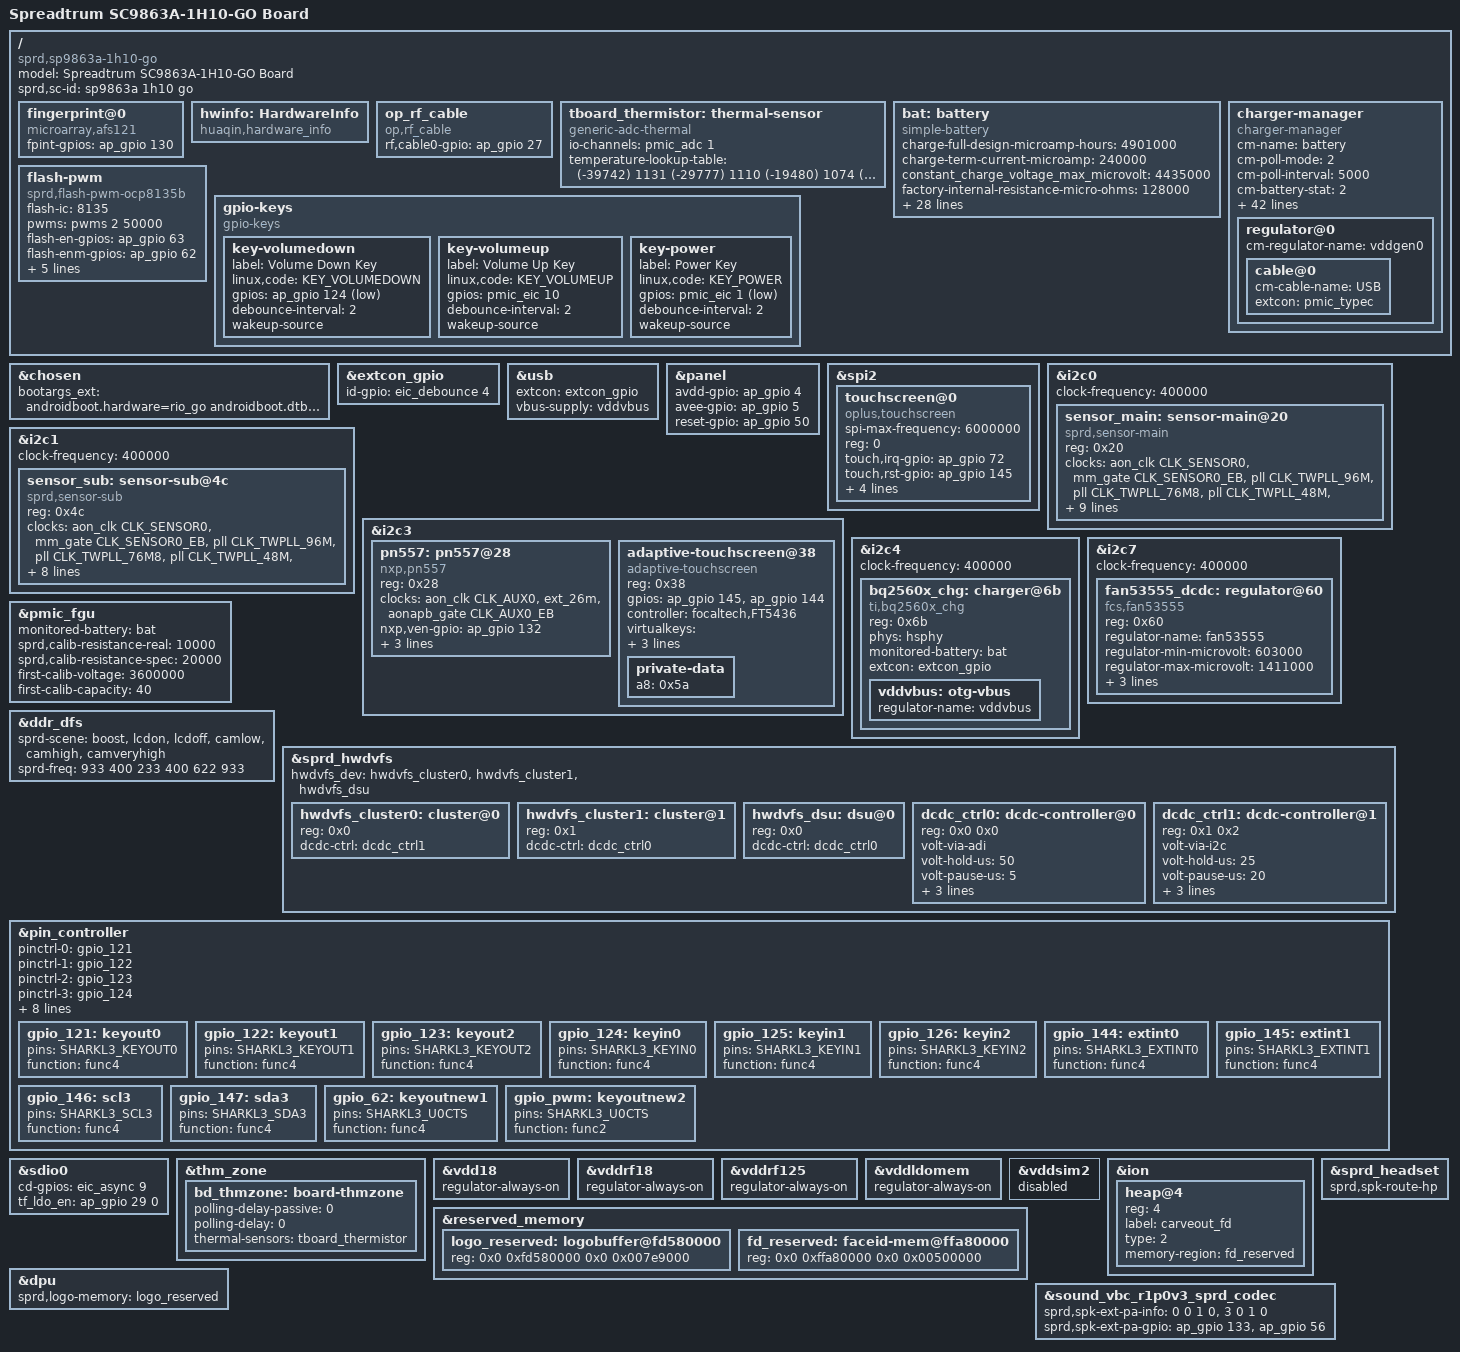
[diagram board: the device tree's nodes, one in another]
/dts-v1/;
/plugin/;

#include <dt-bindings/input/input.h>
#include <dt-bindings/gpio/gpio.h>
#include <dt-bindings/clock/sprd,sc9863a-clk.h>
#include <dt-bindings/pinctrl/pinctrl-sprd.h>
#include "lcd/lcd_jd9365t_ctc_mipi_hd.dtsi"
#include "lcd/lcd_hx83112a_boe_mipi_hd.dtsi"
#include "lcd/lcd_hx83112a_inx_mipi_hd.dtsi"
#include "lcd/lcd_ft8615_inx_mipi_hd.dtsi"
#include "lcd/lcd_ILI9882N_boe_mipi_hd.dtsi"
#include "lcd/lcd_icnl9911C_truly_mipi_hd.dtsi"
#include "lcd/lcd_ft8006s_boe_mipi_hd.dtsi"
#include "lcd/lcd_ft8722_boe_mipi_hd.dtsi"
#include "lcd/lcd_ft8006saa_truly_mipi_hd.dtsi"
#include "lcd/lcd_nt35695_truly_mipi_fhd.dtsi"
#include "lcd/lcd_nt35532_truly_mipi_fhd.dtsi"
#include "lcd/lcd_nt35596_boe_mipi_fhd.dtsi"
#include "lcd/lcd_dummy_mipi.dtsi"


/ {
	model = "Spreadtrum SC9863A-1H10-GO Board";
	compatible = "sprd,sp9863a-1h10-go", "sprd,sc9863a";
	sprd,sc-id = "sp9863a 1h10 go";

	fragment {
		target-path = "/";
		__overlay__ {
			fingerprint@0 {
				compatible = "microarray,afs121";
				fpint-gpios = <&ap_gpio 130 0>;
			};

			hwinfo:HardwareInfo {
				compatible = "huaqin,hardware_info";
				status = "okay";
			};

			op_rf_cable {
				compatible = "op,rf_cable";
				status = "okay";
				rf,cable0-gpio = <&ap_gpio 27 0>;
			};

			tboard_thermistor:thermal-sensor {
				compatible = "generic-adc-thermal";
				#thermal-sensor-cells = <0>;
				io-channels = <&pmic_adc 1>;
				io-channel-names = "sensor-channel";
				temperature-lookup-table = <	(-39742) 1131
								(-29777) 1110
								(-19480) 1074
								(-4679) 983
								10110 838
								24805 654
								44922 413
								54903 316
								64895 238
								74884 178
								84883 133
								94883 100
								104880 75
								114889 57
								124872 43 >;
			};

			bat: battery {
				compatible = "simple-battery";
				charge-full-design-microamp-hours = <4901000>;
				charge-term-current-microamp = <240000>;
				constant_charge_voltage_max_microvolt = <4435000>;
				factory-internal-resistance-micro-ohms = <128000>;
				voltage-min-design-microvolt = <3450000>;
				ocv-capacity-celsius = <20>;
				ocv-capacity-table-0 = <4381000 100>, <4325000 95>, <4268000 90>,
							<4211000 85>, <4154000 80>, <4100000 75>,
							<4049000 70>, <4001000 65>, <3951000 60>,
							<3898000 55>, <3866000 50>, <3840000 45>,
							<3819000 40>, <3802000 35>, <3786000 30>,
							<3765000 25>, <3744000 20>, <3720000 15>,
							<3691000 10>, <3679000 5>, <3400000 0>;
				voltage-temp-table = <1307738 700>, <1203814 750>, <1095466 800>,
							<986111 850>, <878558 900>, <775112 950>,
							<678460 1000>, <590240 1050>, <510772 1100>,
							<440156 1150>, <378279 1200>, <324561 1250>,
							<278079 1300>, <238259 1350>, <204266 1400>,
							<175208 1450>, <150459 1500>, <129410 1550>,
							<111497 1600>, <96484 1650>, <81275 1700>,
							<72771 1750>, <63423 1800>, <55444 1850>,
							<48599 1900>, <42668 1950>, <37552 2000>;
				capacity-temp-table =<45 100>, <25 100>, <10 99>, <0 91>, <(-10) 86>, <(-20) 64>;
				resistance-temp-table =<45 100>, <25 100>, <10 225>, <0 919>, <(-10) 981>, <(-20) 1097>;
				charge-sdp-current-microamp = <500000 2000000>;
				charge-dcp-current-microamp = <2100000 2200000>;
				charge-cdp-current-microamp = <1500000 2100000>;
				charge-unknown-current-microamp = <2100000 2100000>;
			};

			charger-manager {
				status = "okay";
				compatible = "charger-manager";
				cm-name = "battery";
				cm-poll-mode = <2>;
				cm-poll-interval = <5000>;
				cm-battery-stat = <2>;

				cm-fullbatt-vchkdrop-ms = <30000>;
				cm-fullbatt-vchkdrop-volt = <75000>;
				cm-fullbatt-voltage = <4410000>;
				cm-fullbatt-current = <260000>;
				cm-fullbatt-capacity = <100>;

				cm-num-chargers = <1>;
				cm-chargers = "bq2560x_charger";
				cm-fuel-gauge = "sc27xx-fgu";

				/* in deci centigrade */
				cm-battery-cold = <200>;
				cm-battery-cold-in-minus;
				cm-battery-hot = <800>;
				cm-battery-temp-diff = <100>;

				/* Allow charging for 6hr */
				cm-charging-max = <72000000>;
				/* recovery charging after stop charging 45min */
				cm-discharging-max = <2700000>;

				/* the interval to feed charger watchdog */
				cm-wdt-interval = <60>;

				/* drop voltage in microVolts to allow shutdown */
				cm-shutdown-voltage = <3350000>;

				/* when 99% of the time is exceeded, it will be forced to 100% */
				cm-tickle-time-out = <1500>;

				/* how much time to allow capacity change */
				cm-one-cap-time = <30>;

				/* when the safe charging voltage is exceeded, stop charging */
				cm-charge-voltage-max = <6500000>;
				/* drop voltage in microVolts to restart charging */
				cm-charge-voltage-drop = <700000>;
				cm-dcp-jeita-temp-table = <1000 1000 0 4435000>,
					<1150 1150 1400000 4435000>,
					<1450 1450 2100000 4435000>,
					<1530 1530 1400000 4130000>;
				cm-sdp-jeita-temp-table = <1000 1000 0 4435000>,
					<1150 1150 540000 4435000>,
					<1450 1450 540000 4435000>,
					<1530 1530 540000 4130000>;
				cm-cdp-jeita-temp-table = <1000 1000 0 4435000>,
					<1150 1150 1400000 4435000>,
					<1450 1450 1500000 4435000>,
					<1530 1530 1400000 4130000>;
				cm-unknown-jeita-temp-table = <1000 1000 0 4435000>,
					<1150 1150 1400000 4435000>,
					<1450 1450 2100000 4435000>,
					<1530 1530 1400000 4130000>;

				monitored-battery = <&bat>;
				cm-capacity-track;

				cm-cap-remap-table = <1 2 3>, <2 3 2>, <98 99 2>, <99 100 3>;

				io-channels = <&pmic_adc 3>;
				io-channel-names = "batt_id-channel";

				regulator@0 {
					cm-regulator-name = "vddgen0";
					cable@0 {
						cm-cable-name = "USB";
						extcon = <&pmic_typec>;
					};
				};
			};

			flash-pwm {
				compatible = "sprd,flash-pwm-ocp8135b";
				flash-ic = <8135>;
				pwms = <&pwms 2 50000>;
				flash-en-gpios = <&ap_gpio 63 0>;
				flash-enm-gpios = <&ap_gpio 62 0>;

				pinctrl-names = "gpio_pwm","gpio_62";
				pinctrl-0 = <&gpio_pwm>;
				pinctrl-1 = <&gpio_62>;
				board_id1 = <&ap_gpio 34 0>;
				board_id2 = <&ap_gpio 35 0>;
				board_id3 = <&ap_gpio 39 0>;
				status = "okay";
			};

			gpio-keys {
				compatible = "gpio-keys";

				key-volumedown {
					label = "Volume Down Key";
					linux,code = <KEY_VOLUMEDOWN>;
					gpios = <&ap_gpio 124 GPIO_ACTIVE_LOW>;
					debounce-interval = <2>;
					wakeup-source;
				};

				key-volumeup {
					label = "Volume Up Key";
					linux,code = <KEY_VOLUMEUP>;
					gpios = <&pmic_eic 10 GPIO_ACTIVE_HIGH>;
					debounce-interval = <2>;
					wakeup-source;
				};

				key-power {
					label = "Power Key";
					linux,code = <KEY_POWER>;
					gpios = <&pmic_eic 1 GPIO_ACTIVE_LOW>;
					debounce-interval = <2>;
					wakeup-source;
				};
			};
		};
	};
};

&chosen {
	bootargs_ext = "androidboot.hardware=rio_go androidboot.dtbo_idx=0";
};

&extcon_gpio {
 	id-gpio = <&eic_debounce 4 GPIO_ACTIVE_HIGH>;
 };
 
&usb {
	extcon = <&extcon_gpio>;
	vbus-supply = <&vddvbus>;
};

&panel {
	avdd-gpio = <&ap_gpio 4 GPIO_ACTIVE_HIGH>;
	avee-gpio = <&ap_gpio 5 GPIO_ACTIVE_HIGH>;
	reset-gpio = <&ap_gpio 50 GPIO_ACTIVE_HIGH>;
};

&spi2 {
	status = "okay";
	
        touchscreen@0 {
			compatible = "oplus,touchscreen";
			spi-max-frequency = <6000000>;
			reg = <0>;
			touch,irq-gpio = <&ap_gpio 72 0>;
			touch,rst-gpio = <&ap_gpio 145 0>;
			touch,panel-coords = <0 720 0 1600>;
			himax,display-coords = <0 720 0 1600>;
			focaltech,max-touch-number = <10>;
			focaltech,display-coords =  <0 0 720 1600>;
			status ="okay";
		};
};

&i2c0 {
	status = "okay";
	clock-frequency = <400000>;

	sensor_main: sensor-main@20 {
		compatible = "sprd,sensor-main";
		reg = <0x20>;
		clock-names = "clk_src","sensor_eb",
			"clk_96m","clk_76m8",
			"clk_48m","clk_26m";
		clocks = <&aon_clk CLK_SENSOR0>, <&mm_gate CLK_SENSOR0_EB>,
			<&pll CLK_TWPLL_96M>,<&pll CLK_TWPLL_76M8>,
			<&pll CLK_TWPLL_48M>,<&ext_26m>;
		vddio-supply = <&vddcamio>;
		vddcama-supply = <&vddcama>;
		vddcamd-supply = <&vddcamd>;
		vddcammot-supply = <&vddcammot>;
		sprd,phyid = <1>;
		csi = <&csi0>;
		reset-gpios = <&ap_gpio 44 0>;
		power-down-gpios = <&ap_gpio 46 0>;
	};
};

&i2c1 {
	status = "okay";
	clock-frequency = <400000>;

	sensor_sub: sensor-sub@4c {
		compatible = "sprd,sensor-sub";
		reg = <0x4c>;
		clock-names = "clk_src","sensor_eb",
			"clk_96m","clk_76m8",
			"clk_48m","clk_26m";
		clocks = <&aon_clk CLK_SENSOR0>, <&mm_gate CLK_SENSOR0_EB>,
			<&pll CLK_TWPLL_96M>,<&pll CLK_TWPLL_76M8>,
			<&pll CLK_TWPLL_48M>,<&ext_26m>;
		vddio-supply = <&vddcamio>;
		vddcama-supply = <&vddcama>;
		vddcamd-supply = <&vddcamd>;
		/*vddcammot-supply = <&vddcammot>;*/
		sprd,phyid = <2>;
		csi = <&csi0>;
		reset-gpios = <&ap_gpio 45 0>;
		power-down-gpios = <&ap_gpio 40 0>;
	};
};

&i2c3 {
	status = "okay";

        pn557: pn557@28{
                compatible = "nxp,pn557";
                reg = <0x28>;
                clock-names = "pn557_clk","source","enable";
                clocks = <&aon_clk CLK_AUX0>, <&ext_26m>, <&aonapb_gate CLK_AUX0_EB>;
                nxp,ven-gpio = <&ap_gpio 132 0>;
                nxp,irq-gpio = <&ap_gpio 121 0>;
                nxp,firm-gpio = <&ap_gpio 65 0>;
                nxp,clkreq-gpio = <&ap_gpio 66 0>;
        };

	adaptive-touchscreen@38 {
		compatible = "adaptive-touchscreen";
		reg = <0x38>;
		gpios = <&ap_gpio 145 GPIO_ACTIVE_HIGH
			&ap_gpio 144 GPIO_ACTIVE_HIGH>;
		controller = "focaltech,FT5436";
		virtualkeys = <580 60 1320 60 45
			172 360 1320 60 45
			158 600 1320 60 45>;
		surface-width = <720>;
		surface-height = <1280>;

		private-data {
			a8 = /bits/ 8 <0x5a>;
		};
	};

};

&i2c4 {
	status = "okay";
	clock-frequency = <400000>;

	      bq2560x_chg: charger@6b {
              compatible = "ti,bq2560x_chg";
              reg = <0x6b>;
              phys = <&hsphy>;
              monitored-battery = <&bat>;
              extcon = <&extcon_gpio>;
              vddvbus:otg-vbus{
                     regulator-name = "vddvbus";
               };
       };
};

&i2c7 {
	status = "okay";
	clock-frequency = <400000>;

	fan53555_dcdc: regulator@60 {
		compatible = "fcs,fan53555";
		reg = <0x60>;
		regulator-name = "fan53555";
		regulator-min-microvolt = <603000>;
		regulator-max-microvolt = <1411000>;
		regulator-ramp-delay = <64000>;
		regulator-always-on;
		fcs,suspend-voltage-selector = <1>;
	};
};

&pmic_fgu {
	monitored-battery = <&bat>;
	sprd,calib-resistance-real = <10000>;
	sprd,calib-resistance-spec = <20000>;
	first-calib-voltage = <3600000>;
	first-calib-capacity = <40>;
};
/*
&panel {
	sprd,backlight = <&pwm_backlight>;
	sprd,surface-width = <720>;
	sprd,surface-height = <1280>;
};*/

&ddr_dfs {
	sprd-scene = "boost", "lcdon", "lcdoff", "camlow",
			"camhigh", "camveryhigh";
	sprd-freq = <933 400 233 400 622 933>;
};

&sprd_hwdvfs {
	hwdvfs_dev = <&hwdvfs_cluster0>,
		<&hwdvfs_cluster1>,
		<&hwdvfs_dsu>;

	hwdvfs_cluster0: cluster@0 {
		reg = <0x0>;
		dcdc-ctrl = <&dcdc_ctrl1>;
	};

	hwdvfs_cluster1: cluster@1 {
		reg = <0x1>;
		dcdc-ctrl = <&dcdc_ctrl0>;
	};

	hwdvfs_dsu: dsu@0 {
		reg = <0x0>;
		dcdc-ctrl = <&dcdc_ctrl0>;
	};

	dcdc_ctrl0: dcdc-controller@0 {
		reg = <0x0 0x0>;
		volt-via-adi;
		volt-hold-us = <50>;
		volt-pause-us = <5>;
		volt-timeout-us = <800>;
		volt-stable-us  = <5>;
		volt-max-step-microvolt = <25000>;
	};

	dcdc_ctrl1: dcdc-controller@1 {
		reg = <0x1 0x2>;
		volt-via-i2c;
		volt-hold-us = <25>;
		volt-pause-us = <20>;
		volt-timeout-us = <800>;
		volt-stable-us  = <25>;
		volt-max-step-microvolt = <1200004>;
	};
};

&pin_controller {
	pinctrl-names =
	/* keyout0 ~ keyout2 */
	"gpio_121", "gpio_122", "gpio_123",
	/* keyin0 ~ keyin2 */
	"gpio_124", "gpio_125", "gpio_126",
	/* extint0, extint1, scl3, sda3 */
	"gpio_144", "gpio_145", "gpio_146", "gpio_147", "gpio_62", "gpio_pwm";
	pinctrl-0 = <&gpio_121>;
	pinctrl-1 = <&gpio_122>;
	pinctrl-2 = <&gpio_123>;
	pinctrl-3 = <&gpio_124>;
	pinctrl-4 = <&gpio_125>;
	pinctrl-5 = <&gpio_126>;
	pinctrl-6 = <&gpio_144>;
	pinctrl-7 = <&gpio_145>;
	pinctrl-8 = <&gpio_146>;
	pinctrl-9 = <&gpio_147>;
	pinctrl-10 = <&gpio_62>;
	pinctrl-11 = <&gpio_pwm>;

	gpio_121: keyout0 {
		pins = "SHARKL3_KEYOUT0";
		function = "func4";
	};

	gpio_122: keyout1 {
		pins = "SHARKL3_KEYOUT1";
		function = "func4";
	};

	gpio_123: keyout2 {
		pins = "SHARKL3_KEYOUT2";
		function = "func4";
	};

	gpio_124: keyin0 {
		pins = "SHARKL3_KEYIN0";
		function = "func4";
	};

	gpio_125: keyin1 {
		pins = "SHARKL3_KEYIN1";
		function = "func4";
	};

	gpio_126: keyin2 {
		pins = "SHARKL3_KEYIN2";
		function = "func4";
	};

	gpio_144: extint0 {
		pins = "SHARKL3_EXTINT0";
		function = "func4";
	};

	gpio_145: extint1 {
		pins = "SHARKL3_EXTINT1";
		function = "func4";
	};

	gpio_146: scl3 {
		pins = "SHARKL3_SCL3";
		function = "func4";
	};

	gpio_147: sda3 {
		pins = "SHARKL3_SDA3";
		function = "func4";
	};

	gpio_62: keyoutnew1 {
		pins = "SHARKL3_U0CTS";
		function = "func4";
	};

	gpio_pwm: keyoutnew2 {
		pins = "SHARKL3_U0CTS";
		function = "func2";
	};

};

&sdio0 {
	cd-gpios = <&eic_async 9 0>;
	tf_ldo_en = <&ap_gpio 29 0>;
};

&thm_zone {
	bd_thmzone: board-thmzone {
		polling-delay-passive = <0>;
		polling-delay = <0>;
		thermal-sensors = <&tboard_thermistor>;
	};
};

&vdd18 {
	regulator-always-on;
};

&vddrf18 {
	regulator-always-on;
};

&vddrf125 {
	regulator-always-on;
};

&vddldomem {
	regulator-always-on;
};

&vddsim2 {
	status = "disabled";
};

&reserved_memory {
	logo_reserved: logobuffer@fd580000{
		reg = <0x0 0xfd580000 0x0 0x007e9000>;
	};

	fd_reserved: faceid-mem@ffa80000 {
		reg = <0x0 0xffa80000 0x0 0x00500000>;
	};
};

&ion {
	heap@4 {
		reg = <4>;
		label = "carveout_fd";
		type = <2>;
		memory-region = <&fd_reserved>;
	};
};

&dpu {
	sprd,logo-memory = <&logo_reserved>;
};
&sprd_headset {
	status = "okay";
	sprd,spk-route-hp;
};
&sound_vbc_r1p0v3_sprd_codec {
	status = "okay";
	/*ext_control_type, hook selection, mode, gpio share*/
	sprd,spk-ext-pa-info = <0 0 1 0>,<3 0 1 0>;
	sprd,spk-ext-pa-gpio = <&ap_gpio 133 0>,<&ap_gpio 56 0>;
};
